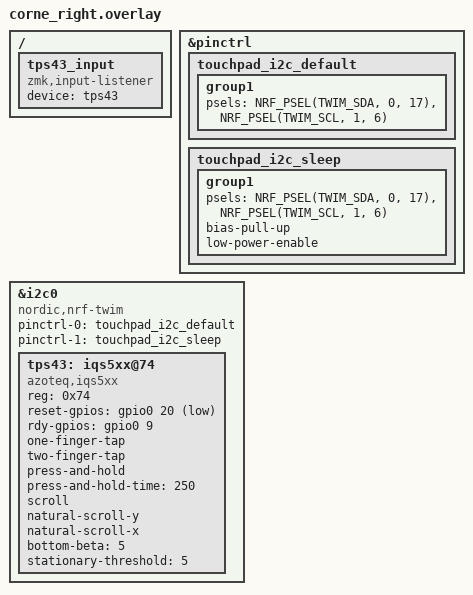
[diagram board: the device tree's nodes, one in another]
&pinctrl {
    touchpad_i2c_default: touchpad_i2c_default {
        group1 {
            psels = <NRF_PSEL(TWIM_SDA, 0, 17)>,
                    <NRF_PSEL(TWIM_SCL, 1, 6)>;
        };
    };

    touchpad_i2c_sleep: touchpad_i2c_sleep {
            group1 {
                psels = <NRF_PSEL(TWIM_SDA, 0, 17)>,
                        <NRF_PSEL(TWIM_SCL, 1, 6)>;
                bias-pull-up;
                low-power-enable;
            };
        };
    };


/ {
    tps43_input: tps43_input {
        compatible = "zmk,input-listener";
        device = <&tps43>;
    };
};

&i2c0 {
    status = "okay";
    compatible = "nordic,nrf-twim";
    pinctrl-0 = <&touchpad_i2c_default>;
    pinctrl-1 = <&touchpad_i2c_sleep>;
    pinctrl-names = "default", "sleep";

    tps43: iqs5xx@74 {
        status = "okay";
        compatible = "azoteq,iqs5xx";
        reg = <0x74>;

        reset-gpios = <&gpio0 20 GPIO_ACTIVE_LOW>;
        rdy-gpios = <&gpio0 9 GPIO_ACTIVE_HIGH>;

        one-finger-tap;
        two-finger-tap;
        press-and-hold;
        press-and-hold-time = <250>;

        scroll;
        natural-scroll-y;
        natural-scroll-x;

        bottom-beta = <5>;
        stationary-threshold = <5>;

        /* enable later if orientation feels wrong */
        // switch-xy;
        // flip-x;
        // flip-y;
    };
};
